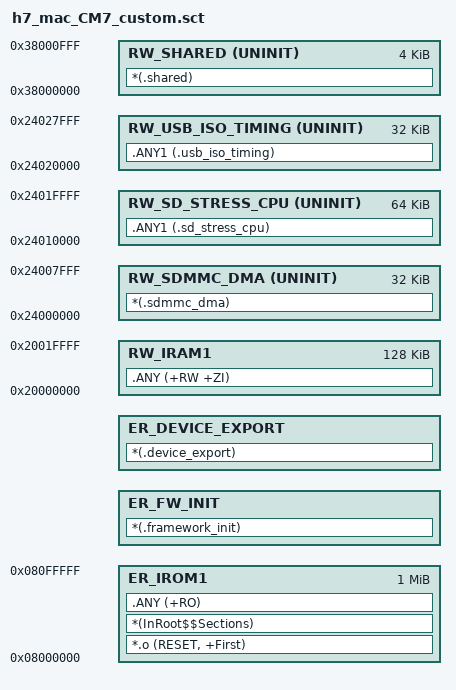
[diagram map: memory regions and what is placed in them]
LR_IROM1 0x08000000 0x00100000
{
    ER_IROM1 0x08000000 0x00100000
    {
        *.o (RESET, +First)
        *(InRoot$$Sections)
        .ANY (+RO)
    }

    ER_FW_INIT +0
    {
        *(.framework_init)
    }

   ER_DEVICE_EXPORT +0
   {
        *(.device_export)
    }

    RW_SHARED 0x38000000 UNINIT 0x00001000
    {
        *(.shared)
    }

    RW_SDMMC_DMA 0x24000000 UNINIT 0x00008000
    {
        *(.sdmmc_dma)
    }

    ; 仅供SD压力测试CPU缓冲，避开前32KiB IDMA区域
    RW_SD_STRESS_CPU 0x24010000 UNINIT 0x00010000
    {
        .ANY1 (.sd_stress_cpu)
    }

    ; USB手动采样记录区，避开SD IDMA与压力缓冲
    RW_USB_ISO_TIMING 0x24020000 UNINIT 0x00008000
    {
        .ANY1 (.usb_iso_timing)
    }

    RW_IRAM1 0x20000000 0x00020000
    {
        .ANY (+RW +ZI)
    }
}
